# PIC18LF8627 register map
Vendor: Microchip
Architecture 18xxxx. Special function registers and configuration words.
Registers are 8-bit, read-write, reset 0x0 unless marked. A register's access mark holds for its fields unless they carry their own. Addresses are absolute, and some are shared; only a register's first bit layout is shown; lines under a group give offsets from that group; [hi:lo] are bit positions; {n}, {i} and the like mark numbered series; 'fields as' and 'values as' point back to an identical list; <NAME> marks a mode.

## Further device data
pins=1: RH2/A18; 2: RH3/A19; 3: RE1/AD9/WR/P2C; 4: RE0/AD8/RD/P2D; 5: RG0/ECCP3/P3A; 6: RG1/TX2/CK2; 7: RG2/RX2/DT2; 8: RG3/CCP4/P3D; 9: RG5/MCLR/Vpp; 10: RG4/CCP5/P1D; 11: Vss; 12: Vdd; 13: RF7/SS1; 14: RF6/AN11; 15: RF5/AN10/CVref; 16: RF4/AN9; 17: RF3/AN8; 18: RF2/AN7/C1OUT; 19: RH7/AN15/P1B; 20: RH6/AN14/P1C; 21: RH5/AN13/P3B; 22: RH4/AN12/P3C; 23: RF1/AN6/C2OUT; 24: RF0/AN5; 25: AVdd; 26: AVss; 27: RA3/AN3/Vref+; 28: RA2/AN2/Vref-; 29: RA1/AN1; 30: RA0/AN0; 31: Vss; 32: Vdd; 33: RA5/AN4/HLVDIN; 34: RA4/T0CKI; 35: RC1/T1OSI/ECCP2/P2A; 36: RC0/T1OSO/T13CKI; 37: RC6/TX1/CK1; 38: RC7/RX1/DT1; 39: RJ4/BA0; 40: RJ5/CE; 41: RJ6/LB; 42: RJ7/UB; 43: RC2/ECCP1/P1A; 44: RC3/SCK1/SCL1; 45: RC4/SDI1/SDA1; 46: RC5/SDO1; 47: RB7/KBI3/PGD; 48: Vdd; 49: OSC1/CLKI/RA7; 50: OSC2/CLKO/RA6; 51: Vss; 52: RB6/KBI2/PGC; 53: RB5/KBI1/PGM; 54: RB4/KBI0; 55: RB3/INT3/ECCP2/P2A; 56: RB2/INT2; 57: RB1/INT1; 58: RB0/INT0/FLT0; 59: RJ3/WRH; 60: RJ2/WRL; 61: RJ1/OE; 62: RJ0/ALE; 63: RD7/AD7/PSP7/SS2; 64: RD6/AD6/PSP6/SCK2/SCL2; 65: RD5/AD5/PSP5/SDI2/SDA2; 66: RD4/AD4/PSP4/SDO2; 67: RD3/AD3/PSP3; 68: RD2/AD2/PSP2; 69: RD1/AD1/PSP1; 70: Vss; 71: Vdd; 72: RD0/AD0/PSP0; 73: RE7/AD15/ECCP2/P2A; 74: RE6/AD14/P1B; 75: RE5/AD13/P1C; 76: RE4/AD12/P3B; 77: RE3/AD11/P3C; 78: RE2/AD10/CS/P2B; 79: RH0/A16; 80: RH1/A17

## CONFIG — Configuration words, addresses in ProgramSpace
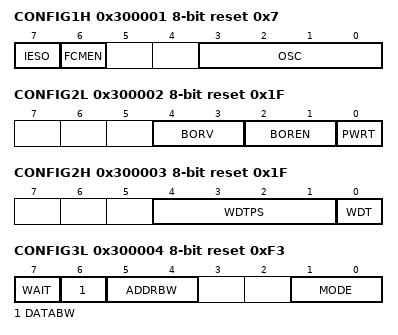
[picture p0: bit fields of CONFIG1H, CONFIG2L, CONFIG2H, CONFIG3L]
0x300001 CONFIG1H reset 0x7
  [7] IESO — Internal/External Oscillator Switchover bit
    0=OFF (Two-Speed Start-up disabled); 1=ON (Two-Speed Start-up enabled)
  [6] FCMEN — Fail-Safe Clock Monitor Enable bit
    0=OFF (Fail-Safe Clock Monitor disabled); 1=ON (Fail-Safe Clock Monitor enabled)
  [3:0] OSC — Oscillator Selection bits
    0b11xx=EC2 (External RC oscillator, CLKO function on RA6); 0b101x=EC1 (External RC oscillator, CLKO function on RA6); 9=INTIO7 (Internal oscillator block, CLKO function on RA6, port function on RA7); 8=INTIO67 (Internal oscillator block, port function on RA6 and RA7); 7=RCIO6 (External RC oscillator, port function on RA6); 6=HSPLL (HS oscillator, PLL enabled (Clock Frequency = 4 x FOSC1)); 5=ECIO6 (EC oscillator, port function on RA6); 4=EC (EC oscillator, CLKO function on RA6); 3=RC (External RC oscillator, CLKO function on RA6); 2=HS (HS oscillator); 1=XT (XT oscillator); 0=LP (LP oscillator)
0x300002 CONFIG2L reset 0x1F
  [4:3] BORV — Brown-out Voltage bits
    3=Minimum setting; 2=2; 1=1; 0=Maximum setting
  [2:1] BOREN — Brown-out Reset Enable bits
    3=SBORDIS (Brown-out Reset enabled in hardware only (SBOREN is disabled)); 2=NOSLP (Brown-out Reset enabled in hardware only and disabled in Sleep mode (SBOREN is disabled)); 1=ON (Brown-out Reset enabled and controlled by software (SBOREN is enabled)); 0=OFF (Brown-out Reset disabled in hardware and software)
  [0] PWRT — Power-up Timer Enable bit
    1=OFF (PWRT disabled); 0=ON (PWRT enabled)
0x300003 CONFIG2H reset 0x1F
  [4:1] WDTPS — Watchdog Timer Postscale Select bits
    15=1:32768; 14=1:16384; 13=1:8192; 12=1:4096; 11=1:2048; 10=1:1024; 9=1:512; 8=1:256; 7=1:128; 6=1:64; 5=1:32; 4=1:16; 3=1:8; 2=1:4; 1=1:2; 0=1:1
  [0] WDT — Watchdog Timer
    1=ON (WDT enabled); 0=OFF (WDT disabled (control is placed on the SWDTEN bit))
0x300004 CONFIG3L reset 0xF3
  [7] WAIT — External Bus Data Wait Enable bit
    1=OFF (Wait selections are unavailable for table reads and table writes); 0=ON (Wait selections for table reads and table writes are determined by the WAIT1:WAIT0 bits)
  [6] DATABW — Data Bus Width Select bit
    1=DATA16BIT (16-bit External Bus mode); 0=DATA8BIT (8-bit External Bus mode)
  [5:4] ADDRBW — Address Bus Width Select bits
    3=ADDR20BIT (20-bit Address Bus); 2=ADDR16BIT (16-bit Address Bus); 1=ADDR12BIT (12-bit Address Bus); 0=ADDR8BIT (8-bit Address Bus)
  [1:0] MODE — Processor Data Memory Mode Select bits
    3=MC (Microcontroller mode); 2=MP (Microprocessor mode); 1=MPB (Microprocessor with Boot Block mode); 0=EM (Extended Microcontroller mode)
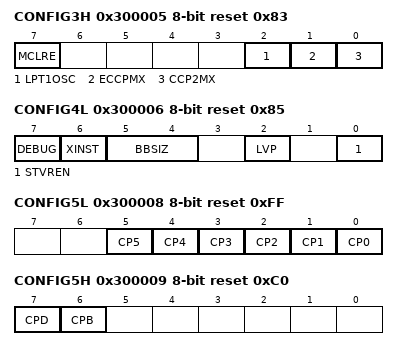
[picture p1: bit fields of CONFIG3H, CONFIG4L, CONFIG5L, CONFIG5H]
0x300005 CONFIG3H reset 0x83
  [7] MCLRE — MCLR Pin Enable bit
    1=ON (MCLR pin enabled; RG5 input pin disabled); 0=OFF (RG5 input pin enabled; MCLR disabled)
  [2] LPT1OSC — Low-Power Timer1 Oscillator Enable bit
    1=ON (Timer1 configured for low-power operation); 0=OFF (Timer1 configured for higher power operation)
  [1] ECCPMX — ECCP MUX bit
    1=PORTE (ECCP1/3 (P1B/P1C/P3B/P3C) are multiplexed onto RE6, RE5, RE4 and RE3 respectively); 0=PORTH (ECCP1/3 (P1B/P1C/P3B/P3C) are multiplexed onto RH7, RH6, RH5 and RH4 respectively)
  [0] CCP2MX — CCP2 MUX bit
    1=PORTC (ECCP2 input/output is multiplexed with RC1); 0=PORTBE (ECCP2 is multiplexed with RB3 in Extended Microcontroller, Microprocessor or Microprocessor with Boot Block mode. Or with RE7 in Microcontroller mode.)
0x300006 CONFIG4L reset 0x85
  [7] DEBUG — Background Debugger Enable bit
    1=OFF (Background debugger disabled, RB6 and RB7 configured as general purpose I/O pins); 0=ON (Background debugger enabled, RB6 and RB7 are dedicated to In-Circuit Debug)
  [6] XINST — Extended Instruction Set Enable bit
    1=ON (Instruction set extension and Indexed Addressing mode enabled); 0=OFF (Instruction set extension and Indexed Addressing mode disabled (Legacy mode))
  [5:4] BBSIZ — Boot Block Size Select bits
    0b1x=BB8K (4K words (8 Kbytes) Boot Block size); 1=BB4K (2K words (4 Kbytes) Boot Block size); 0=BB2K (1K word (2 Kbytes) Boot Block size)
  [2] LVP — Single-Supply ICSP Enable bit
    1=ON (Single-Supply ICSP enabled); 0=OFF (Single-Supply ICSP disabled)
  [0] STVREN — Stack Full/Underflow Reset Enable bit
    1=ON (Stack full/underflow will cause Reset); 0=OFF (Stack full/underflow will not cause Reset)
0x300008 CONFIG5L reset 0xFF
  [5] CP5 — Code Protection bit Block 5
    1=OFF (Block 5 (014000-017FFFh) not code-protected); 0=ON (Block 5 (014000-017FFFh) code-protected)
  [4] CP4 — Code Protection bit Block 4
    1=OFF (Block 4 (010000-013FFFh) not code-protected); 0=ON (Block 4 (010000-013FFFh) code-protected)
  [3] CP3 — Code Protection bit Block 3
    1=OFF (Block 3 (00C000-00FFFFh) not code-protected); 0=ON (Block 3 (00C000-00FFFFh) code-protected)
  [2] CP2 — Code Protection bit Block 2
    1=OFF (Block 2 (008000-00BFFFh) not code-protected); 0=ON (Block 2 (008000-00BFFFh) code-protected)
  [1] CP1 — Code Protection bit Block 1
    1=OFF (Block 1 (004000-007FFFh) not code-protected); 0=ON (Block 1 (004000-007FFFh) code-protected)
  [0] CP0 — Code Protection bit Block 0
    1=OFF (Block 0 (000800, 001000 or 002000-003FFFh) not code-protected); 0=ON (Block 0 (000800, 001000 or 002000-003FFFh) code-protected)
0x300009 CONFIG5H reset 0xC0
  [7] CPD — Data EEPROM Code Protection bit
    1=OFF (Data EEPROM not code-protected); 0=ON (Data EEPROM code-protected)
  [6] CPB — Boot Block Code Protection bit
    1=OFF (Boot Block (000000-0007FFh) not code-protected); 0=ON (Boot Block (000000-0007FFh) code-protected)
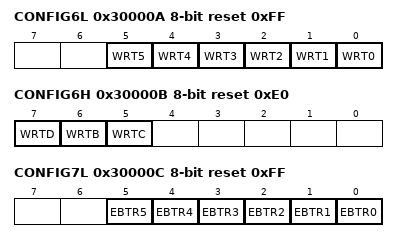
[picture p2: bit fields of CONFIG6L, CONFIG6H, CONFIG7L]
0x30000A CONFIG6L reset 0xFF
  [5] WRT5 — Write Protection bit Block 5
    1=OFF (Block 5 (014000-017FFFh) not write-protected); 0=ON (Block 5 (014000-017FFFh) write-protected)
  [4] WRT4 — Write Protection bit Block 4
    1=OFF (Block 4 (010000-013FFFh) not write-protected); 0=ON (Block 4 (010000-013FFFh) write-protected)
  [3] WRT3 — Write Protection bit Block 3
    1=OFF (Block 3 (00C000-00FFFFh) not write-protected); 0=ON (Block 3 (00C000-00FFFFh) write-protected)
  [2] WRT2 — Write Protection bit Block 2
    1=OFF (Block 2 (008000-00BFFFh) not write-protected); 0=ON (Block 2 (008000-00BFFFh) write-protected)
  [1] WRT1 — Write Protection bit Block 1
    1=OFF (Block 1 (004000-007FFFh) not write-protected); 0=ON (Block 1 (004000-007FFFh) write-protected)
  [0] WRT0 — Write Protection bit Block 0
    1=OFF (Block 0 (000800, 001000 or 002000-003FFFh) not write-protected); 0=ON (Block 0 (000800, 001000 or 002000-003FFFh) write-protected)
0x30000B CONFIG6H reset 0xE0
  [7] WRTD — Data EEPROM Write Protection bit
    1=OFF (Data EEPROM not write-protected); 0=ON (Data EEPROM write-protected)
  [6] WRTB — Boot Block Write Protection bit
    1=OFF (Boot Block (000000-007FFF, 000FFF or 001FFFh) not write-protected); 0=ON (Boot Block (000000-007FFF, 000FFF or 001FFFh) write-protected)
  [5] WRTC — Configuration Register Write Protection bit
    1=OFF (Configuration registers (300000-3000FFh) not write-protected); 0=ON (Configuration registers (300000-3000FFh) write-protected)
0x30000C CONFIG7L reset 0xFF
  [5] EBTR5 — Table Read Protection bit Block 5
    1=OFF (Block 5 (014000-017FFFh) not protected from table reads executed in other blocks); 0=ON (Block 5 (014000-017FFFh) protected from table reads executed in other blocks)
  [4] EBTR4 — Table Read Protection bit Block 4
    1=OFF (Block 4 (010000-013FFFh) not protected from table reads executed in other blocks); 0=ON (Block 4 (010000-013FFFh) protected from table reads executed in other blocks)
  [3] EBTR3 — Table Read Protection bit Block 3
    1=OFF (Block 3 (00C000-00FFFFh) not protected from table reads executed in other blocks); 0=ON (Block 3 (00C000-00FFFFh) protected from table reads executed in other blocks)
  [2] EBTR2 — Table Read Protection bit Block 2
    1=OFF (Block 2 (008000-00BFFFh) not protected from table reads executed in other blocks); 0=ON (Block 2 (008000-00BFFFh) protected from table reads executed in other blocks)
  [1] EBTR1 — Table Read Protection bit Block 1
    1=OFF (Block 1 (004000-007FFFh) not protected from table reads executed in other blocks); 0=ON (Block 1 (004000-007FFFh) protected from table reads executed in other blocks)
  [0] EBTR0 — Table Read Protection bit Block 0
    1=OFF (Block 0 (000800, 001000 or 002000-003FFFh) not protected from table reads executed in other blocks); 0=ON (Block 0 (000800, 001000 or 002000-003FFFh) protected from table reads executed in other blocks)
0x30000D CONFIG7H reset 0x40
  [6] EBTRB — Boot Block Table Read Protection bit
    1=OFF (Boot Block (000000-007FFF, 000FFF or 001FFFh) not protected from table reads executed in other blocks); 0=ON (Boot Block (000000-007FFF, 000FFF or 001FFFh) protected from table reads executed in other blocks)
